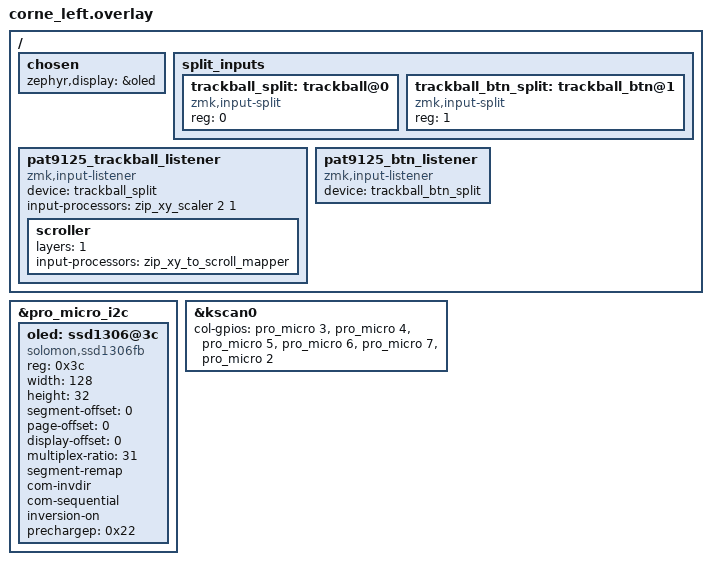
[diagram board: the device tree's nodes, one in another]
#include "corne.dtsi"
#include <input/processors.dtsi>

/ {
    chosen {
        zephyr,display = &oled;
    };

    split_inputs {
        #address-cells = <1>;
        #size-cells = <0>;

        trackball_split: trackball@0 {
            compatible = "zmk,input-split";
            reg = <0>;
        };

        trackball_btn_split: trackball_btn@1 {
            compatible = "zmk,input-split";
            reg = <1>;
        };
    };

    pat9125_trackball_listener {
        compatible = "zmk,input-listener";
        device = <&trackball_split>;
        input-processors = <&zip_xy_scaler 2 1>;

        scroller {
            layers = <1>;
            input-processors = <&zip_xy_to_scroll_mapper>;
        };
    };

    pat9125_btn_listener {
        compatible = "zmk,input-listener";
        device = <&trackball_btn_split>;
    };
};

/*
 * Corne v3 standard 0.91" OLED (SSD1306 128x32) on I2C.
 * Socket on PCB uses nice!nano default I2C: SDA pin 2, SCL pin 3.
 */
&pro_micro_i2c {
    status = "okay";

    oled: ssd1306@3c {
        compatible = "solomon,ssd1306fb";
        reg = <0x3c>;
        width = <128>;
        height = <32>;
        segment-offset = <0>;
        page-offset = <0>;
        display-offset = <0>;
        multiplex-ratio = <31>;
        segment-remap;
        com-invdir;
        com-sequential;
        inversion-on;
        prechargep = <0x22>;
    };
};

&kscan0 {
    col-gpios = <&pro_micro 3 GPIO_ACTIVE_HIGH>,
                <&pro_micro 4 GPIO_ACTIVE_HIGH>,
                <&pro_micro 5 GPIO_ACTIVE_HIGH>,
                <&pro_micro 6 GPIO_ACTIVE_HIGH>,
                <&pro_micro 7 GPIO_ACTIVE_HIGH>,
                <&pro_micro 2 GPIO_ACTIVE_HIGH>;
};
